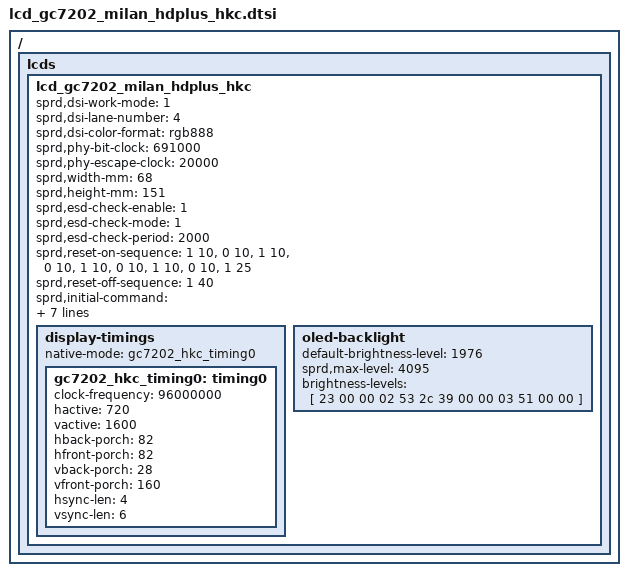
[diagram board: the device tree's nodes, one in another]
/ {
	fragment {
		target-path = "/";

		__overlay__ {
			lcds {
				lcd_gc7202_milan_hdplus_hkc: lcd_gc7202_milan_hdplus_hkc {

					sprd,dsi-work-mode = <1>;
					sprd,dsi-lane-number = <4>;
					sprd,dsi-color-format = "rgb888";

					sprd,phy-bit-clock = <691000>;
					sprd,phy-escape-clock = <20000>;

					sprd,width-mm = <68>;
					sprd,height-mm = <151>;

					sprd,esd-check-enable = <1>;
					sprd,esd-check-mode = <1>;  /*Read register*/
					sprd,esd-check-period = <2000>;
					/* sprd,esd-check-register = <0x0A>;
					sprd,esd-check-value = <0x9C>; */

                    sprd,reset-on-sequence = <1 10>, <0 10>,<1 10>,<0 10>, <1 10>,<0 10>,<1 10>,<0 10>,<1 25>;
					sprd,reset-off-sequence = <1 40>;

					sprd,initial-command = [
							39 00 00 04 FF 55 AA 66
                            23 00 00 02 FF 20
                            23 00 00 02 FB 00
							23 00 00 02 FF 21
							23 00 00 02 FB 00
							23 00 00 02 FF 22
							23 00 00 02 FB 00
							23 00 00 02 FF 23
							23 00 00 02 FB 00
							23 00 00 02 FF 24
							23 00 00 02 FB 00
							23 00 00 02 FF 26
							23 00 00 02 FB 00
							23 00 00 02 FF 27
							23 00 00 02 FB 00
							23 00 00 02 FF A3
							23 00 00 02 FB 00
							23 00 00 02 FF B3
							23 00 00 02 FB 00
							23 00 00 02 FF C3
							23 00 00 02 FB 00
							23 00 00 02 FF 10
							23 00 00 02 FB 00



							23 00 00 02 FF 20
							23 00 00 02 18 44
							23 00 00 02 17 52
							23 00 00 02 15 5D
							23 00 00 02 12 A1
							23 00 00 02 A5 00
							23 00 00 02 A6 FF
							23 00 00 02 A9 00
							23 00 00 02 AA FF
							23 00 00 02 D3 05
							23 00 00 02 2D 1f


							23 00 00 02 FF B3
							23 00 00 02 3E 03
							23 00 00 02 58 84
							23 00 00 02 82 1A
							23 00 00 02 FF 22
							23 00 00 02 1f 06
							23 00 00 02 FF C3
							23 00 00 02 06 44
							23 00 00 02 13 07

							23 00 00 02 FF 20
							23 00 00 02 A3 44
							23 00 00 02 A7 44
							23 00 00 02 FF B3
							23 00 00 02 3F 37
							23 00 00 02 5E 10

							23 00 00 02 FF 22
                                                        23 00 00 02 E4 00
                                                        23 00 00 02 01 06
                                                        23 00 00 02 02 40
                                                        23 00 00 02 25 08
                                                        23 00 00 02 26 00
                                                        23 00 00 02 2E 8F
                                                        23 00 00 02 2F 00
                                                        23 00 00 02 36 0A
                                                        23 00 00 02 37 00
                                                        23 00 00 02 3F 8F
                                                        23 00 00 02 40 00
  
							23 00 00 02 FF 21
							23 00 00 02 01 25
							23 00 00 02 02 25
							23 00 00 02 03 23
							23 00 00 02 04 23
							23 00 00 02 05 1E
							23 00 00 02 06 03
							23 00 00 02 07 1F
							23 00 00 02 08 19
							23 00 00 02 09 1F
							23 00 00 02 0A 09
							23 00 00 02 0B 0B
							23 00 00 02 0C 0D
							23 00 00 02 0D 0F
							23 00 00 02 0E 01
							23 00 00 02 0F 25
							23 00 00 02 10 25
							23 00 00 02 11 25
							23 00 00 02 12 25
							23 00 00 02 13 25
							23 00 00 02 14 25
							23 00 00 02 15 25
							23 00 00 02 16 25
							23 00 00 02 17 23
							23 00 00 02 18 23
							23 00 00 02 19 23
							23 00 00 02 1A 23
							23 00 00 02 1B 1E
							23 00 00 02 1C 02
							23 00 00 02 1D 1F
							23 00 00 02 1E 19
							23 00 00 02 1F 1F
							23 00 00 02 20 08
							23 00 00 02 21 0A
							23 00 00 02 22 0C
							23 00 00 02 23 0E
							23 00 00 02 24 00
							23 00 00 02 25 25
							23 00 00 02 26 25
							23 00 00 02 27 25
							23 00 00 02 28 25
							23 00 00 02 29 25
							23 00 00 02 2A 25
							23 00 00 02 2B 25
							23 00 00 02 2D 25
							23 00 00 02 7E 03
							23 00 00 02 7F 23
							23 00 00 02 8B 23
							23 00 00 02 80 07
							23 00 00 02 8C 03
							23 00 00 02 81 03
							23 00 00 02 8D 07
							23 00 00 02 AF 40
							23 00 00 02 B0 40
							23 00 00 02 83 02
							23 00 00 02 8F 02
							23 00 00 02 84 55
							23 00 00 02 90 55
							23 00 00 02 85 50
							23 00 00 02 91 50
							23 00 00 02 87 02
							23 00 00 02 93 06
							23 00 00 02 82 B0
							23 00 00 02 8E B0
							23 00 00 02 2E 00
							23 00 00 02 88 B7
							23 00 00 02 89 20
							23 00 00 02 8A 53
							23 00 00 02 94 B7
							23 00 00 02 95 20
							23 00 00 02 96 53
							23 00 00 02 45 0F
							23 00 00 02 46 BB
							23 00 00 02 4C BB
							23 00 00 02 52 B2
							23 00 00 02 58 B2
							23 00 00 02 47 0b
							23 00 00 02 4D 0a
							23 00 00 02 53 22
							23 00 00 02 59 23
							23 00 00 02 48 23
							23 00 00 02 4E 22
							23 00 00 02 54 09
							23 00 00 02 5A 0A
							23 00 00 02 76 40
							23 00 00 02 77 40
							23 00 00 02 78 40
							23 00 00 02 79 40
							23 00 00 02 49 5d
							23 00 00 02 4A 50
							23 00 00 02 4F 5d
							23 00 00 02 50 50
							23 00 00 02 55 55
							23 00 00 02 56 50
							23 00 00 02 5B 55
							23 00 00 02 5C 50
							23 00 00 02 BE 03
							23 00 00 02 C0 44
							23 00 00 02 C1 40
							23 00 00 02 BF BB
							23 00 00 02 C2 8B
							23 00 00 02 C3 8B
							23 00 00 02 C6 42
							23 00 00 02 C7 54
							23 00 00 02 D1 13
							23 00 00 02 BB 22
							23 00 00 02 B3 A6
							23 00 00 02 B4 0c
							23 00 00 02 BC 70
							23 00 00 02 B7 A6
							23 00 00 02 B8 0c
							23 00 00 02 BD 74
							23 00 00 02 FF 22
							23 00 00 02 05 10
							23 00 00 02 08 23

							23 00 00 02 FF 20
							23 00 00 02 25 12

							23 00 00 02 FF 20
							23 00 00 02 C3 00
							23 00 00 02 C4 5F
							23 00 00 02 C5 00
							23 00 00 02 C6 5F
							23 00 00 02 B3 00
							23 00 00 02 B4 20
							23 00 00 02 B5 00
							23 00 00 02 B6 DC
  
							23 00 00 02 FF 20
                                                        23 00 00 02 02 44
							23 00 00 02 03 44
							23 00 00 02 04 4f
							23 00 00 02 05 4f
							23 00 00 02 0A 44
							23 00 00 02 0B 44
							23 00 00 02 0C 4f
							23 00 00 02 0D 4f
							23 00 00 02 77 99
							23 00 00 02 78 A0

 
							23 00 00 02 7E 01
							23 00 00 02 7F 00
							23 00 00 02 80 01
							23 00 00 02 81 00
							23 00 00 02 82 00
							23 00 00 02 83 04
							23 00 00 02 84 04
							23 00 00 02 85 01
							23 00 00 02 86 90
							23 00 00 02 87 01
							23 00 00 02 88 90
							23 00 00 02 8A 03
							23 00 00 02 8B 03
							23 00 00 02 FF 20
							23 00 00 02 50 0F
							23 00 00 02 51 21

							23 00 00 02 FF 23
							23 00 00 02 25 03
							39 00 00 11 01 00 00 00 01 00 07 00 16 00 2C 00 38 00 47 00 54
							39 00 00 11 02 00 60 00 8E 00 B3 00 EC 01 1D 01 6B 01 B4 01 B6
							39 00 00 11 03 02 06 02 65 02 A0 02 E9 03 18 03 4F 03 60 03 72
							39 00 00 0D 04 03 85 03 9A 03 B2 03 CE 03 ED 03 FF

							39 00 00 11 0D 00 00 00 01 00 07 00 16 00 2C 00 38 00 47 00 54
							39 00 00 11 0E 00 60 00 8E 00 B3 00 EC 01 1D 01 6B 01 B4 01 B6
							39 00 00 11 0F 02 06 02 65 02 A0 02 E9 03 18 03 4F 03 60 03 72
							39 00 00 0D 10 03 85 03 9A 03 B2 03 CE 03 ED 03 FF
							23 00 00 02 2E 00
							23 00 00 02 2d 61
							23 00 00 02 32 01
							23 00 00 02 33 2e
      							23 00 00 02 FF A3
							23 00 00 02 FA 01
							23 00 00 02 05 05
							23 00 00 02 FF 22
							23 00 00 02 EF 07

							23 00 00 02 FF 10
							39 00 00 03 51 00 00
							23 00 00 02 53 2C
							23 00 00 02 55 00
							23 00 00 02 36 08
							23 00 00 02 69 00
							23 00 00 02 35 00

							23 78 00 02 11 00
							23 00 00 02 FF 27
							39 00 00 07 03 40 10 08 00 F3 0C
							39 32 00 0E 04 03 24 80 44 4C 54 AD 05 00 00 1C E0 10

							23 00 00 02 FF 10
							23 32 00 02 29 00
						];
			sprd,page-unlock-command = [
		39 00 00 04 FF 55 AA 66 
						];
					sprd,sleep-in-command = [
						39 00 00 04 FF 55 AA 66

						23 00 00 02 FF 27
						39 00 00 07 03 40 10 08 00 00 00
						39 00 00 0E 04 03 24 80 44 4C 54 AD 05 00 00 1C 00 00

						23 00 00 02 FF 21
						23 00 00 02 D1 03

						23 00 00 02 FF 20
						23 00 00 02 4A 01
						23 00 00 02 48 10
						23 00 00 02 49 00


						23 00 00 02 FF A3
						23 00 00 02 0F 01
						23 00 00 02 0E 03

						23 00 00 02 FF 10
						23 00 00 02 28 00

						23 78 00 02 10 00

						23 00 00 02 FF A3
						23 00 00 02 0F 00
						23 00 00 02 0E 00

						39 00 00 04 FF 55 AA 66
						23 00 00 02 FF 26
						23 00 00 02 FB 00
						39 00 00 05 1D A2 AA AA 0A
						23 00 00 02 FF 10
						23 00 00 02 FB 00
						23 00 00 02 4F 01

						];
					sprd,sleep-out-command = [
						39 00 00 04 FF 55 AA 66

						23 00 00 02 FF 27
						39 00 00 07 03 40 10 08 00 00 00
						39 00 00 0E 04 03 24 80 44 4C 54 AD 05 00 00 1C 00 00

						23 00 00 02 FF 21
						23 00 00 02 D1 03

						23 00 00 02 FF 20
						23 00 00 02 4A 01
						23 00 00 02 48 10
						23 00 00 02 49 00

						23 00 00 02 FF A3
						23 00 00 02 0F 01
						23 00 00 02 0E 03

						23 00 00 02 FF 10
						23 00 00 02 28 00

						23 78 00 02 10 00

						23 00 00 02 FF A3
						23 00 00 02 0F 00
						23 00 00 02 0E 00
						23 00 00 02 4F 01
						];

					display-timings {
						native-mode = <&gc7202_hkc_timing0>;

						gc7202_hkc_timing0: timing0 {
							clock-frequency = <96000000>;
				hactive = <720>;
				vactive = <1600>;
				hback-porch = <82>;
				hfront-porch = <82>;
				vback-porch = <28>;
				vfront-porch = <160>;
				hsync-len = <4>;
				vsync-len = <6>;
						};
					};
				oled-backlight {
						default-brightness-level = <1976>;
						sprd,max-level = <4095>;
						brightness-levels = [
							23 00 00 02 53 2c
							39 00 00 03 51 00 00
							];
					};
				};
			};
		};
	};
};

